VERSION "HFUT RES CAN validation contract v1.0"

NS_ :

BS_:

BU_: RES VCU TESTER

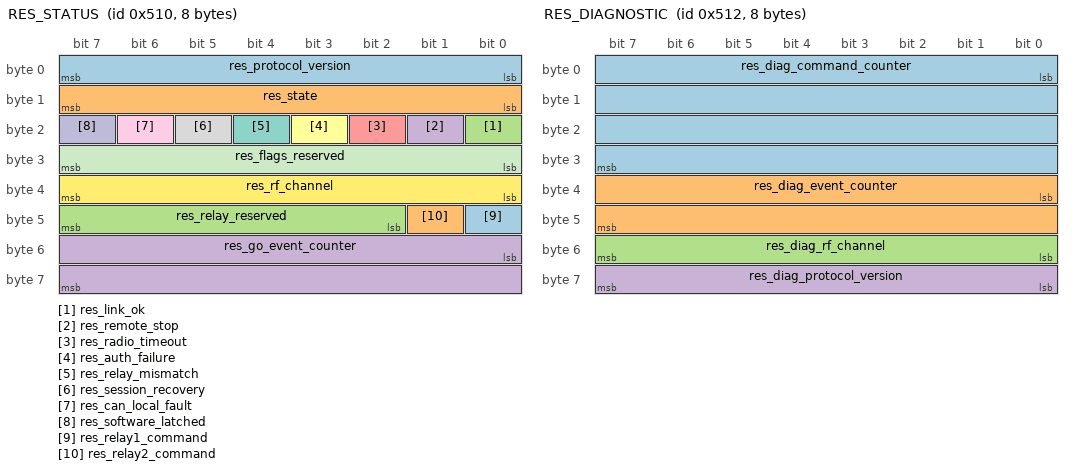
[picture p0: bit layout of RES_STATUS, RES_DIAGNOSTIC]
BO_ 1296 RES_STATUS: 8 RES
 SG_ res_protocol_version : 0|8@1+ (1,0) [0|255] "" VCU,TESTER
 SG_ res_state : 8|8@1+ (1,0) [0|4] "" VCU,TESTER
 SG_ res_link_ok : 16|1@1+ (1,0) [0|1] "" VCU,TESTER
 SG_ res_remote_stop : 17|1@1+ (1,0) [0|1] "" VCU,TESTER
 SG_ res_radio_timeout : 18|1@1+ (1,0) [0|1] "" VCU,TESTER
 SG_ res_auth_failure : 19|1@1+ (1,0) [0|1] "" VCU,TESTER
 SG_ res_relay_mismatch : 20|1@1+ (1,0) [0|1] "" VCU,TESTER
 SG_ res_session_recovery : 21|1@1+ (1,0) [0|1] "" VCU,TESTER
 SG_ res_can_local_fault : 22|1@1+ (1,0) [0|1] "" VCU,TESTER
 SG_ res_software_latched : 23|1@1+ (1,0) [0|1] "" VCU,TESTER
 SG_ res_flags_reserved : 24|8@1+ (1,0) [0|255] "" VCU,TESTER
 SG_ res_rf_channel : 32|8@1+ (1,0) [0|255] "" VCU,TESTER
 SG_ res_relay1_command : 40|1@1+ (1,0) [0|1] "" VCU,TESTER
 SG_ res_relay2_command : 41|1@1+ (1,0) [0|1] "" VCU,TESTER
 SG_ res_relay_reserved : 42|6@1+ (1,0) [0|63] "" VCU,TESTER
 SG_ res_go_event_counter : 48|16@1+ (1,0) [0|65535] "" VCU,TESTER

BO_ 1297 RES_GO_EVENT: 8 RES
 SG_ res_go_remote_session : 0|32@1+ (1,0) [0|4294967295] "" VCU,TESTER
 SG_ res_go_command_counter : 32|32@1+ (1,0) [0|4294967295] "" VCU,TESTER

BO_ 1298 RES_DIAGNOSTIC: 8 RES
 SG_ res_diag_command_counter : 0|32@1+ (1,0) [0|4294967295] "" VCU,TESTER
 SG_ res_diag_event_counter : 32|16@1+ (1,0) [0|65535] "" VCU,TESTER
 SG_ res_diag_rf_channel : 48|8@1+ (1,0) [0|255] "" VCU,TESTER
 SG_ res_diag_protocol_version : 56|8@1+ (1,0) [0|255] "" VCU,TESTER

CM_ "Standalone DBC for bench and vehicle verification of the RES-to-VCU Classic CAN interface. Nominal bus speed is 500 kbit/s.";
CM_ BO_ 1296 "Standard ID 0x510. Cyclic RES status sent every 50 ms. VCU shall treat a protocol mismatch, invalid state, any safety fault flag, relay inconsistency, or a message timeout greater than 150 ms as RES_ERROR.";
CM_ SG_ 1296 res_protocol_version "CAN payload contract version. Current value is 1.";
CM_ SG_ 1296 res_state "Receiver safety state. STOPPED_FAULT is latched for an authenticated STOP or radio timeout.";
CM_ SG_ 1296 res_link_ok "1 when the receiver has a current authenticated radio link; 0 otherwise.";
CM_ SG_ 1296 res_remote_stop "1 after an authenticated remote STOP has been accepted.";
CM_ SG_ 1296 res_radio_timeout "1 after no valid authenticated radio frame has been accepted for 500 ms.";
CM_ SG_ 1296 res_auth_failure "1 when CRC, authentication, session, sequence or replay validation has failed.";
CM_ SG_ 1296 res_relay_mismatch "1 when commanded and locally checked relay states are inconsistent.";
CM_ SG_ 1296 res_session_recovery "1 while a new authenticated remote session is being qualified.";
CM_ SG_ 1296 res_can_local_fault "1 when the RES receiver detects a local CAN transmit fault.";
CM_ SG_ 1296 res_software_latched "1 when a receiver safety fault has been latched. Same-session READY frames shall not clear it.";
CM_ SG_ 1296 res_flags_reserved "Reserved. The transmitter shall send 0; any other value is a protocol fault.";
CM_ SG_ 1296 res_rf_channel "Current automatic hopping channel index. Valid implemented values are 0, 1 and 2.";
CM_ SG_ 1296 res_relay1_command "Logical command: 0=open/released, 1=closed/energized. This is not a mechanical contact feedback signal.";
CM_ SG_ 1296 res_relay2_command "Logical command: 0=open/released, 1=closed/energized. This is not a mechanical contact feedback signal.";
CM_ SG_ 1296 res_relay_reserved "Reserved. The transmitter shall send 0.";
CM_ SG_ 1296 res_go_event_counter "Accepted GO event counter, wrapping modulo 65536.";
CM_ BO_ 1297 "Standard ID 0x511. Event frame emitted once for each newly authenticated operator GO action. It never overrides STOP, timeout or another safety fault.";
CM_ SG_ 1297 res_go_remote_session "Authenticated remote boot session associated with the GO event.";
CM_ SG_ 1297 res_go_command_counter "Monotonic GO command counter associated with the event.";
CM_ BO_ 1298 "Standard ID 0x512. Diagnostic companion to 0x511, emitted for traceability of an accepted GO event.";
CM_ SG_ 1298 res_diag_command_counter "Diagnostic copy of the accepted GO command counter.";
CM_ SG_ 1298 res_diag_event_counter "Diagnostic copy of the local accepted GO event counter.";
CM_ SG_ 1298 res_diag_rf_channel "RF channel on which the GO command was accepted.";
CM_ SG_ 1298 res_diag_protocol_version "Diagnostic protocol version. Current value is 1.";

BA_DEF_ BO_ "GenMsgCycleTime" INT 0 65535;
BA_DEF_ BO_ "GenMsgSendType" ENUM "Cyclic","Event";
BA_DEF_DEF_ "GenMsgCycleTime" 0;
BA_DEF_DEF_ "GenMsgSendType" "Cyclic";
BA_ "GenMsgCycleTime" BO_ 1296 50;
BA_ "GenMsgSendType" BO_ 1297 1;
BA_ "GenMsgSendType" BO_ 1298 1;

VAL_ 1296 res_state 0 "BOOT" 1 "WAIT_LINK" 2 "READY" 3 "GO_EVENT" 4 "STOPPED_FAULT" ;
VAL_ 1296 res_link_ok 0 "NO_VALID_LINK" 1 "AUTHENTICATED_LINK" ;
VAL_ 1296 res_remote_stop 0 "NOT_RECEIVED" 1 "STOP_ACCEPTED" ;
VAL_ 1296 res_radio_timeout 0 "NO_TIMEOUT" 1 "TIMEOUT_500MS" ;
VAL_ 1296 res_auth_failure 0 "NO_AUTH_FAULT" 1 "AUTH_OR_FRAME_FAULT" ;
VAL_ 1296 res_relay_mismatch 0 "CONSISTENT" 1 "MISMATCH" ;
VAL_ 1296 res_session_recovery 0 "NOT_RECOVERING" 1 "RECOVERING" ;
VAL_ 1296 res_can_local_fault 0 "CAN_OK" 1 "CAN_LOCAL_FAULT" ;
VAL_ 1296 res_software_latched 0 "NOT_LATCHED" 1 "SAFETY_LATCHED" ;
VAL_ 1296 res_rf_channel 0 "CHANNEL_0" 1 "CHANNEL_1" 2 "CHANNEL_2" ;
VAL_ 1296 res_relay1_command 0 "OPEN" 1 "CLOSED" ;
VAL_ 1296 res_relay2_command 0 "OPEN" 1 "CLOSED" ;
